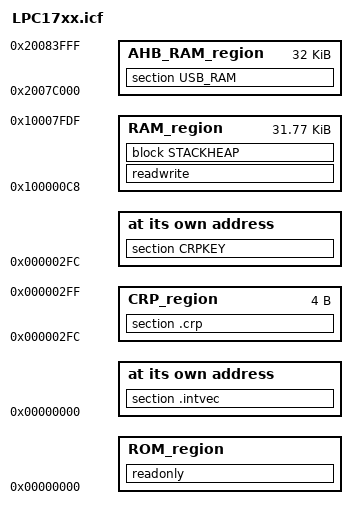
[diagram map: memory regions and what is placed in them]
/* [ROM] */
define symbol __intvec_start__     = 0x00000000;
define symbol __region_ROM_start__ = 0x00000000;
define symbol __CRP_start__        = 0x000002FC;
define symbol __CRP_end__          = 0x000002FF;
define symbol __region_ROM_end__   = 0x0007FFFF;

/* [RAM] Vector table dynamic copy: 8_byte_aligned(49 vect * 4 bytes) =  8_byte_aligned(0xC4) = 0xC8*/
define symbol __NVIC_start__       = 0x10000000;
define symbol __NVIC_end__         = 0x100000C7;
define symbol __region_RAM_start__ = 0x100000C8;
define symbol __region_RAM_end__   = 0x10007FDF;
define symbol _AHB_RAM_start__     = 0x2007C000;
define symbol _AHB_RAM_end__       = 0x20083FFF;

/* Memory regions */
define memory mem with size = 4G;

define region ROM_region     = mem:[from __region_ROM_start__   to __region_ROM_end__] - mem:[from  __CRP_start__ to __CRP_end__];
define region CRP_region     = mem:[from  __CRP_start__ to __CRP_end__];

define region RAM_region     = mem:[from __region_RAM_start__   to __region_RAM_end__];
define region AHB_RAM_region = mem:[from _AHB_RAM_start__ to _AHB_RAM_end__];

/* Stack and Heap */
define symbol __size_cstack__   = 0x800;
define symbol __size_heap__     = 0x800;
define block CSTACK    with alignment = 8, size = __size_cstack__   { };
define block HEAP      with alignment = 8, size = __size_heap__     { };
define block STACKHEAP with fixed order { block HEAP, block CSTACK };

initialize by copy with packing = zeros { readwrite };
do not initialize  { section .noinit };

place at address mem:__intvec_start__ { section .intvec };
place at address mem:0x2FC { section CRPKEY };
place in ROM_region     { readonly };
place in RAM_region     { readwrite, block STACKHEAP };
place in AHB_RAM_region { section USB_RAM };
place in CRP_region     { section .crp };
